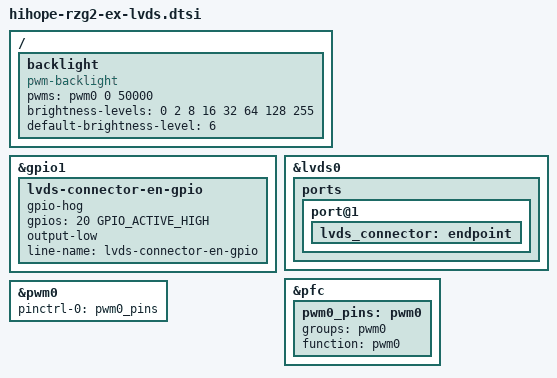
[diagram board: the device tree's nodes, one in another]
// SPDX-License-Identifier: GPL-2.0
/*
 * Device Tree Source for the RZ/G2[MN] HiHope sub board LVDS common parts
 *
 * Copyright (C) 2020 Renesas Electronics Corp.
 */

/ {
	backlight {
		compatible = "pwm-backlight";
		pwms = <&pwm0 0 50000>;

		brightness-levels = <0 2 8 16 32 64 128 255>;
		default-brightness-level = <6>;
	};
};

&gpio1 {
	/*
	 * When GP1_20 is LOW LVDS0 is connected to the LVDS connector
	 * When GP1_20 is HIGH LVDS0 is connected to the LT8918L
	 */
	lvds-connector-en-gpio {
		gpio-hog;
		gpios = <20 GPIO_ACTIVE_HIGH>;
		output-low;
		line-name = "lvds-connector-en-gpio";
	};
};

&lvds0 {
	ports {
		port@1 {
			lvds_connector: endpoint {
			};
		};
	};
};

&pfc {
	pwm0_pins: pwm0 {
		groups = "pwm0";
		function = "pwm0";
	};
};

&pwm0 {
	pinctrl-0 = <&pwm0_pins>;
	pinctrl-names = "default";

	status = "okay";
};
